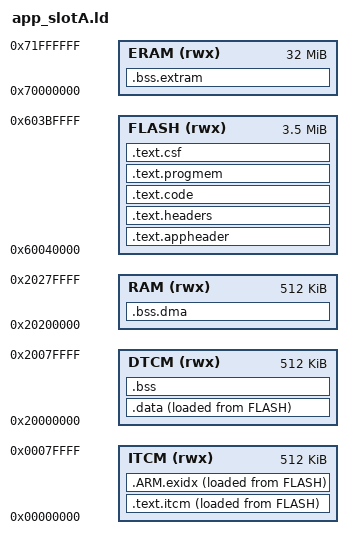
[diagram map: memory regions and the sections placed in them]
/* OTA boot prototype - application linker script (slot A).
 *
 * Based on the stock Teensy 4.1 script (imxrt1062_t41.ld) with three changes:
 *   1. FLASH ORIGIN moved to the slot base (0x60040000); LENGTH bounded to the
 *      slot. The stock startup copies ITCM/DATA from LOADADDR(...) symbols that
 *      the linker computes relative to FLASH ORIGIN, so moving ORIGIN is all it
 *      takes for the unmodified Teensy startup to copy from the right slot.
 *   2. ENTRY is the app's ResetHandler (the ROM never boots this image; the
 *      bootloader branches to it directly).
 *   3. An .appheader section is pinned to the slot base so the bootloader can
 *      find the magic + entry point at a fixed address. The stock FCB/IVT boot
 *      header is still emitted (those symbols are `used`) but is dead weight
 *      here - it just sits after the app header and is never read.
 *
 * ITCM/DTCM/RAM/ERAM are identical to stock: RAM is shared and re-initialised by
 * the app's own ResetHandler after the handoff.
 */
MEMORY
{
	ITCM (rwx):  ORIGIN = 0x00000000, LENGTH = 512K
	DTCM (rwx):  ORIGIN = 0x20000000, LENGTH = 512K
	RAM (rwx):   ORIGIN = 0x20200000, LENGTH = 512K
	FLASH (rwx): ORIGIN = 0x60040000, LENGTH = 3584K   /* slot A, after 256K bootloader */
	ERAM (rwx):  ORIGIN = 0x70000000, LENGTH = 32768K
}

ENTRY(ResetHandler)

SECTIONS
{
	/* App header at the very slot base so the bootloader finds it at a fixed
	   address. ALIGN(1024) keeps the following (unused) FCB clear of it. */
	.text.appheader ORIGIN(FLASH) : {
		KEEP(*(.appheader))
		. = ALIGN(1024);
	} > FLASH

	.text.headers : {
		KEEP(*(.flashconfig))
		FILL(0xFF)
		. = ORIGIN(FLASH) + 0x1000;
		KEEP(*(.ivt))
		KEEP(*(.bootdata))
		. = ALIGN(1024);
	} > FLASH

	.text.code : {
		KEEP(*(.startup))
		*(.flashmem*)
		. = ALIGN(4);
		KEEP(*(.init))
		__preinit_array_start = .;
		KEEP (*(.preinit_array))
		__preinit_array_end = .;
		__init_array_start = .;
		KEEP (*(.init_array))
		__init_array_end = .;
		. = ALIGN(4);
	} > FLASH

	.text.progmem : {
		*(.progmem*)
		. = ALIGN(4);
	} > FLASH

	.text.itcm : {
		. = . + 32; /* MPU to trap NULL pointer deref */
		*(.fastrun)
		*(.text*)
		. = ALIGN(16);
	} > ITCM  AT> FLASH

	.ARM.exidx : {
		__exidx_start = .;
		*(.ARM.exidx* .ARM.extab.text* .gnu.linkonce.armexidx.*)
		__exidx_end = .;
	} > ITCM  AT> FLASH

	.data : {
		*(.endpoint_queue)
		*(SORT_BY_ALIGNMENT(SORT_BY_NAME(.rodata*)))
		*(SORT_BY_ALIGNMENT(SORT_BY_NAME(.data*)))
		KEEP(*(.vectorsram))
	} > DTCM  AT> FLASH

	.bss ALIGN(4) : {
		*(SORT_BY_ALIGNMENT(SORT_BY_NAME(.bss*)))
		*(SORT_BY_ALIGNMENT(SORT_BY_NAME(COMMON)))
		. = ALIGN(32);
		. = . + 32; /* MPU to trap stack overflow */
	} > DTCM

	.bss.dma (NOLOAD) : {
		*(.hab_log)
		*(.dmabuffers)
		. = ALIGN(32);
	} > RAM

	.bss.extram (NOLOAD) : {
		*(SORT_BY_ALIGNMENT(SORT_BY_NAME(.externalram)))
		. = ALIGN(32);
	} > ERAM

	.text.csf : {
		FILL(0xFF)
		. = ALIGN(1024);
		KEEP(*(.csf))
		__text_csf_end = .;
	} > FLASH

	_stext = ADDR(.text.itcm);
	_etext = ADDR(.text.itcm) + SIZEOF(.text.itcm) + SIZEOF(.ARM.exidx);
	_stextload = LOADADDR(.text.itcm);

	_sdata = ADDR(.data);
	_edata = ADDR(.data) + SIZEOF(.data);
	_sdataload = LOADADDR(.data);

	_sbss = ADDR(.bss);
	_ebss = ADDR(.bss) + SIZEOF(.bss);

	_heap_start = ADDR(.bss.dma) + SIZEOF(.bss.dma);
	_heap_end = ORIGIN(RAM) + LENGTH(RAM);

	_extram_start = ADDR(.bss.extram);
	_extram_end = ADDR(.bss.extram) + SIZEOF(.bss.extram);

	_itcm_block_count = (SIZEOF(.text.itcm) + SIZEOF(.ARM.exidx) + 0x7FFF) >> 15;
	_flexram_bank_config = 0xAAAAAAAA | ((1 << (_itcm_block_count * 2)) - 1);
	_estack = ORIGIN(DTCM) + ((16 - _itcm_block_count) << 15);

	_flashimagelen = __text_csf_end - ORIGIN(FLASH);
	_teensy_model_identifier = 0x25;

	.debug_info     0 : { *(.debug_info) }
	.debug_abbrev   0 : { *(.debug_abbrev) }
	.debug_line     0 : { *(.debug_line) }
	.debug_frame    0 : { *(.debug_frame) }
	.debug_str      0 : { *(.debug_str) }
	.debug_loc      0 : { *(.debug_loc) }

}
